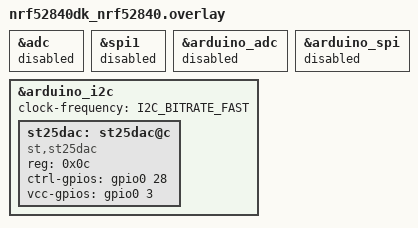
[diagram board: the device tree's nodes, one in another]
/*
 * Copyright (c) 2026 Nordic Semiconductor ASA
 * SPDX-License-Identifier: Apache-2.0
 *
 * ST-NUCLEO-NFC stacked on nRF52840 DK Arduino UNO R3 headers.
 *
 * Shield wiring when stacked on Arduino UNO R3
 *   SDA  -> D14     -> P0.26  (arduino_i2c / TWI)
 *   SCL  -> D15     -> P0.27  (arduino_i2c / TWI)
 *   VCC  -> A0      -> P0.03  (tag supply enable)
 *   CTRL -> A2      -> P0.28  (BiDir wake; open-drain + shield pull-up)
 *   3V3 (direct)
 *   GND (direct)
 */

#include <zephyr/dt-bindings/gpio/nordic-nrf-gpio.h>

&adc {
	status = "disabled";
};

&spi1 {
	status = "disabled";
};

&arduino_adc {
	status = "disabled";
};

&arduino_spi {
	status = "disabled";
};

&arduino_i2c {
	status = "okay";
	/delete-property/ zephyr,pm-device-runtime-auto;
	clock-frequency = <I2C_BITRATE_FAST>;

	st25dac: st25dac@c {
		compatible = "st,st25dac";
		reg = <0x0c>;
		status = "okay";
		ctrl-gpios = <&gpio0 28 (GPIO_OPEN_DRAIN | GPIO_ACTIVE_HIGH)>;
		vcc-gpios = <&gpio0 3 (GPIO_PUSH_PULL | GPIO_ACTIVE_HIGH | NRF_GPIO_DRIVE_H0H1)>;
	};
};
